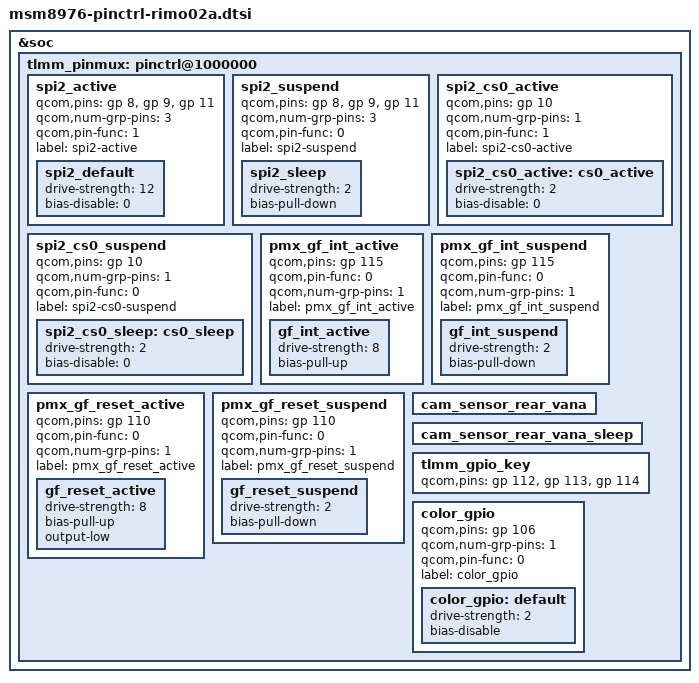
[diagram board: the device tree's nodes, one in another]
&soc {
       tlmm_pinmux: pinctrl@1000000 {
                spi2_active {
                        /* MOSI, MISO, CLK */
                        qcom,pins = <&gp 8>, <&gp 9>, <&gp 11>;
                        qcom,num-grp-pins = <3>;
                        qcom,pin-func = <1>;
                        label = "spi2-active";
                        /* active state */
                        spi2_default: spi2_default {
                                drive-strength = <12>; /* 12 MA */
                                bias-disable = <0>; /* No PULL */
                        };
                };

                spi2_suspend {
                        /* MOSI, MISO, CLK */
                        qcom,pins = <&gp 8>, <&gp 9>, <&gp 11>;
                        qcom,num-grp-pins = <3>;
                        qcom,pin-func = <0>;
                        label = "spi2-suspend";
                        /* suspended state */
                        spi2_sleep: spi2_sleep {
                                drive-strength = <2>; /* 2 MA */
                                bias-pull-down; /* PULL Down */
                        };
                };
                spi2_cs0_active {
                        /* CS */
                        qcom,pins = <&gp 10>;
                        qcom,num-grp-pins = <1>;
                        qcom,pin-func = <1>;
                        label = "spi2-cs0-active";
                        spi2_cs0_active: cs0_active {
                                drive-strength = <2>;
                                bias-disable = <0>;
                        };
                };

                spi2_cs0_suspend {
                        /* CS */
                        qcom,pins = <&gp 10>;
                        qcom,num-grp-pins = <1>;
                        qcom,pin-func = <0>;
                        label = "spi2-cs0-suspend";
                        spi2_cs0_sleep: cs0_sleep {
                                drive-strength = <2>;
                                bias-disable = <0>;
                        };
                };

		/* add pingrp for fingerprint */
		pmx_gf_int_active {
			qcom,pins = <&gp 115>;
			qcom,pin-func = <0>;
			qcom,num-grp-pins = <1>;
			label = "pmx_gf_int_active";

			gf_int_active: gf_int_active {
				drive-strength = <8>;
				bias-pull-up;
			};
		};

		pmx_gf_int_suspend {
			qcom,pins = <&gp 115>;
			qcom,pin-func = <0>;
			qcom,num-grp-pins = <1>;
			label = "pmx_gf_int_suspend";

			gf_int_suspend: gf_int_suspend {
				drive-strength = <2>;
				bias-pull-down;
			};
		};

		pmx_gf_reset_active {
			qcom,pins = <&gp 110>;
			qcom,pin-func = <0>;
			qcom,num-grp-pins = <1>;
			label = "pmx_gf_reset_active";

			gf_reset_active: gf_reset_active {
				drive-strength = <8>;
				bias-pull-up;
				output-low;
			};
		};

		pmx_gf_reset_suspend {
			qcom,pins = <&gp 110>;
			qcom,pin-func = <0>;
			qcom,num-grp-pins = <1>;
			label = "pmx_gf_reset_suspend";

			gf_reset_suspend: gf_reset_suspend {
				drive-strength = <2>;
				bias-pull-down;
			};
		};

		cam_sensor_rear_vana {
                        /delete-property/ qcom,pins;
                };

		cam_sensor_rear_vana_sleep {
                        /delete-property/ qcom,pins;
                };

		tlmm_gpio_key: tlmm_gpio_key {
                        /delete-property/ qcom,pins;
			qcom,pins = <&gp 112>, <&gp 113>, <&gp 114>;
                };
		color_gpio {
                        qcom,pins = <&gp 106>;
			qcom,num-grp-pins = <1>;
			qcom,pin-func = <0>;
			label = "color_gpio";

			color_gpio: default {
			        drive-strength = <2>;
				bias-disable;
			};
                };
	};
};
